# STM32H743 register map
File version: 2.4
CPU: CM7 r0p1, little endian, MPU, FPU, 4 interrupt priority bits
Registers are 32-bit, read-write, reset 0x0 unless marked. A register's access mark holds for its fields unless they carry their own. Offsets are from the block's base; [hi:lo] are bit positions; {n}, {i} and the like mark numbered series.

## LPUART1
Base 0x58000C00
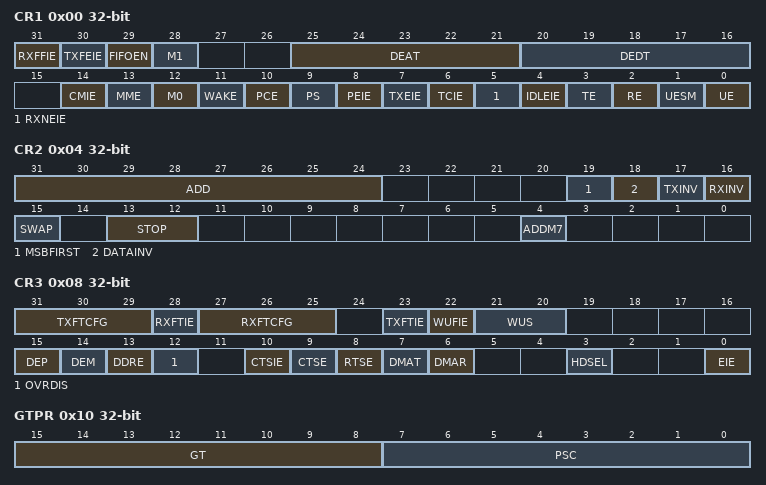
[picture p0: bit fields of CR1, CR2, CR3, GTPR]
0x00 CR1 — 控制寄存器 1
  [31] RXFFIE — 接收 FIFO 满中断使能
  [30] TXFEIE — 发送 FIFO 空中断使能
  [29] FIFOEN — FIFO 模式使能
  [28] M1 — 字长
  [25:21] DEAT — 驱动使能建立时间
  [20:16] DEDT — 驱动使能释放时间
  [14] CMIE — 字符匹配中断使能
  [13] MME — 静默模式使能
  [12] M0 — 字长
  [11] WAKE — 接收器唤醒方式
  [10] PCE — 校验控制使能
  [9] PS — 校验位选择
  [8] PEIE — 校验错误中断使能
  [7] TXEIE — 发送数据寄存器空中断使能
  [6] TCIE — 发送完成中断使能
  [5] RXNEIE — 接收数据寄存器非空中断使能
  [4] IDLEIE — 空闲线路中断使能
  [3] TE — 发送器使能
  [2] RE — 接收器使能
  [1] UESM — 停止模式下 USART 使能
  [0] UE — USART 使能
0x04 CR2 — 控制寄存器 2
  [31:24] ADD — USART 节点地址
  [19] MSBFIRST — 高位在前
  [18] DATAINV — 二进制数据取反
  [17] TXINV — TX 引脚有效电平取反
  [16] RXINV — RX 引脚有效电平取反
  [15] SWAP — TX/RX 引脚交换
  [13:12] STOP — 停止位
  [4] ADDM7 — 7 位地址检测 / 4 位地址检测
0x08 CR3 — 控制寄存器 3
  [31:29] TXFTCFG — 发送 FIFO 阈值配置
  [28] RXFTIE — 接收 FIFO 阈值中断使能
  [27:25] RXFTCFG — 接收 FIFO 阈值配置
  [23] TXFTIE — 发送 FIFO 阈值中断使能
  [22] WUFIE — 停止模式唤醒中断使能
  [21:20] WUS — 停止模式唤醒中断标志选择
  [15] DEP — 驱动使能极性选择
  [14] DEM — 驱动使能模式
  [13] DDRE — 接收错误时禁用 DMA
  [12] OVRDIS — 溢出禁用
  [10] CTSIE — CTS 中断使能
  [9] CTSE — CTS 使能
  [8] RTSE — RTS 使能
  [7] DMAT — DMA 发送使能
  [6] DMAR — DMA 接收使能
  [3] HDSEL — 半双工选择
  [0] EIE — 错误中断使能
0x0C BRR — 波特率寄存器
  [19:0] BRR — 波特率值
0x10 GTPR — 保护时间和预分频器寄存器
  [15:8] GT — 保护时间值
  [7:0] PSC — 预分频器值
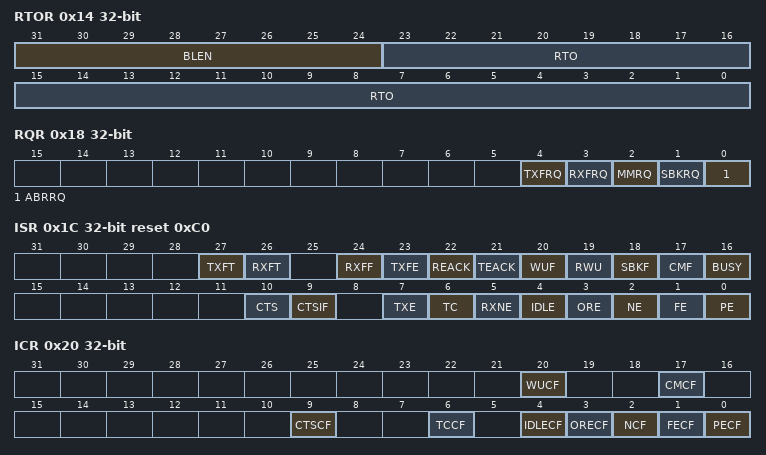
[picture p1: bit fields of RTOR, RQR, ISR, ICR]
0x14 RTOR — 接收超时寄存器
  [31:24] BLEN — 块长度
  [23:0] RTO — 接收超时值
0x18 RQR wo — 请求寄存器
  [4] TXFRQ — 发送数据刷新请求
  [3] RXFRQ — 接收数据刷新请求
  [2] MMRQ — 静默模式请求
  [1] SBKRQ — 发送间隔符请求
  [0] ABRRQ — 自动波特率请求
0x1C ISR ro reset 0xC0 — 中断和状态寄存器
  [27] TXFT — 发送 FIFO 阈值标志
  [26] RXFT — 接收 FIFO 阈值标志
  [24] RXFF — 接收 FIFO 满
  [23] TXFE — 发送 FIFO 空
  [22] REACK — 接收器使能确认
  [21] TEACK — 发送器使能确认
  [20] WUF — 停止模式唤醒标志
  [19] RWU — 接收器静默
  [18] SBKF — 间隔符标志
  [17] CMF — 字符匹配标志
  [16] BUSY — 忙标志
  [10] CTS — CTS 标志
  [9] CTSIF — CTS 中断标志
  [7] TXE — 发送数据寄存器空
  [6] TC — 发送完成
  [5] RXNE — 接收数据寄存器非空
  [4] IDLE — 空闲线路检测
  [3] ORE — 溢出错误
  [2] NE — 噪声错误
  [1] FE — 帧错误
  [0] PE — 校验错误
0x20 ICR wo — 中断标志清除寄存器
  [20] WUCF — 停止模式唤醒清除标志
  [17] CMCF — 字符匹配清除标志
  [9] CTSCF — CTS 清除标志
  [6] TCCF — 发送完成清除标志
  [4] IDLECF — 空闲线路检测清除标志
  [3] ORECF — 溢出错误清除标志
  [2] NCF — 噪声检测清除标志
  [1] FECF — 帧错误清除标志
  [0] PECF — 校验错误清除标志
0x24 RDR ro — 接收数据寄存器
  [8:0] RDR — 接收数据值
0x28 TDR — 发送数据寄存器
  [8:0] TDR — 发送数据值
0x2C PRESC — 预分频器寄存器
  [3:0] PRESCALER — 时钟预分频器

## SYSCFG — 系统配置控制器
Base 0x58000400
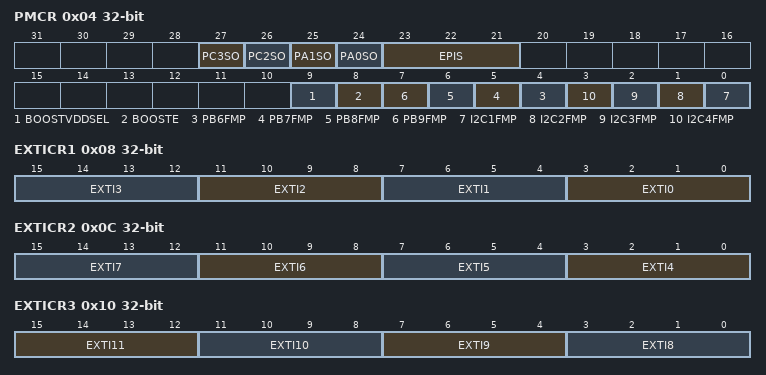
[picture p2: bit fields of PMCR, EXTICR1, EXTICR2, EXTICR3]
0x04 PMCR — 外设模式配置寄存器
  [27] PC3SO — PC3 开关断开
  [26] PC2SO — PC2 开关断开
  [25] PA1SO — PA1 开关断开
  [24] PA0SO — PA0 开关断开
  [23:21] EPIS — 以太网 PHY 接口选择
  [9] BOOSTVDDSEL — 模拟开关电源电压选择
  [8] BOOSTE — 升压器使能
  [n-2] PB{n}FMP (n=6..9) — PB{n} 快速模式+
  [n-1] I2C{n}FMP (n=1..4) — I2C{n} 快速模式+
0x08 EXTICR1 — 外部中断配置寄存器 1
  [4n+3:4n] EXTI{n} (n=0..3) — EXTIx 配置（x = 0 至 3）
0x0C EXTICR2 — 外部中断配置寄存器 2
  [4n-13:4n-16] EXTI{n} (n=4..7) — EXTIx 配置（x = 4 至 7）
0x10 EXTICR3 — 外部中断配置寄存器 3
  [15:12] EXTI11 — EXTIx 配置（x = 8 至 11）
  [11:8] EXTI10 — EXTI10 配置
  [7:4] EXTI9 — EXTIx 配置（x = 8 至 11）
  [3:0] EXTI8 — EXTIx 配置（x = 8 至 11）
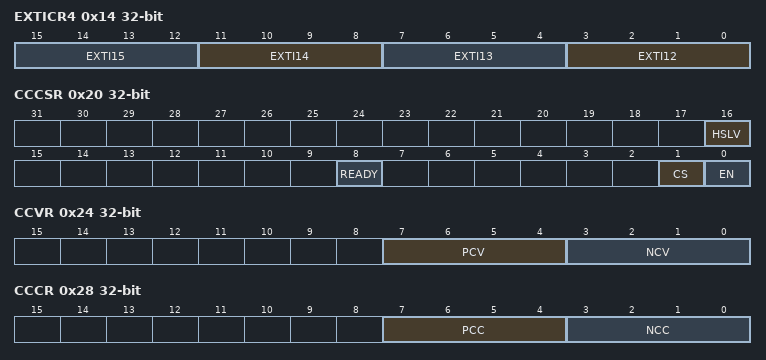
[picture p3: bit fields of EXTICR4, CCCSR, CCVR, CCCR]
0x14 EXTICR4 — 外部中断配置寄存器 4
  [4n-45:4n-48] EXTI{n} (n=12..15) — EXTIx 配置（x = 12 至 15）
0x20 CCCSR — 补偿单元控制/状态寄存器
  [16] HSLV — 低压高速模式
  [8] READY — 补偿单元就绪标志
  [1] CS — 代码选择
  [0] EN — 使能
0x24 CCVR ro — SYSCFG 补偿单元值寄存器
  [7:4] PCV — PMOS 补偿值
  [3:0] NCV — NMOS 补偿值
0x28 CCCR — SYSCFG 补偿单元代码寄存器
  [7:4] PCC — PMOS 补偿代码
  [3:0] NCC — NMOS 补偿代码
0x2C PWRCR — SYSCFG 电源控制寄存器
  [3:0] ODEN — 超速模式使能
0x124 PKGR ro — SYSCFG 封装寄存器
  [3:0] PKG — 封装类型
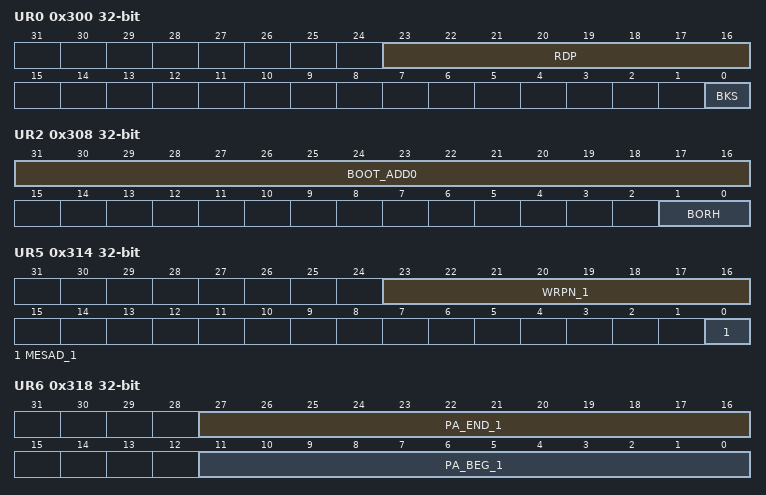
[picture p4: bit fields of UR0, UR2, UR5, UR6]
0x300 UR0 ro — SYSCFG 用户寄存器 0
  [23:16] RDP — 读出保护
  [0] BKS — 存储体交换
0x308 UR2 — SYSCFG 用户寄存器 2
  [31:16] BOOT_ADD0 — 启动地址 0
  [1:0] BORH — 欠压复位阈值等级
0x30C UR3 — SYSCFG 用户寄存器 3
  [31:16] BOOT_ADD1 — 启动地址 1
0x310 UR4 ro — SYSCFG 用户寄存器 4
  [16] MEPAD_1 — 存储体 1 禁用批量擦除保护区
0x314 UR5 ro — SYSCFG 用户寄存器 5
  [23:16] WRPN_1 — Flash 存储体 1 写保护
  [0] MESAD_1 — 存储体 1 禁用批量擦除安全区
0x318 UR6 ro — SYSCFG 用户寄存器 6
  [27:16] PA_END_1 — 存储体 1 保护区结束地址
  [11:0] PA_BEG_1 — 存储体 1 保护区起始地址
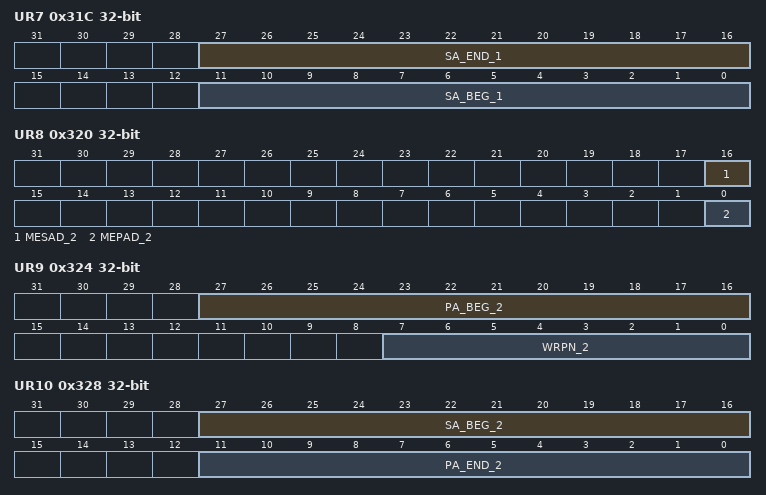
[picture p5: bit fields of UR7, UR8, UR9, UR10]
0x31C UR7 ro — SYSCFG 用户寄存器 7
  [27:16] SA_END_1 — 存储体 1 安全区结束地址
  [11:0] SA_BEG_1 — 存储体 1 安全区起始地址
0x320 UR8 ro — SYSCFG 用户寄存器 8
  [16] MESAD_2 — 存储体 2 禁用批量擦除安全区
  [0] MEPAD_2 — 存储体 2 禁用批量擦除保护区
0x324 UR9 ro — SYSCFG 用户寄存器 9
  [27:16] PA_BEG_2 — 存储体 2 保护区起始地址
  [7:0] WRPN_2 — Flash 存储体 2 写保护
0x328 UR10 ro — SYSCFG 用户寄存器 10
  [27:16] SA_BEG_2 — 存储体 2 安全区起始地址
  [11:0] PA_END_2 — 存储体 2 保护区结束地址
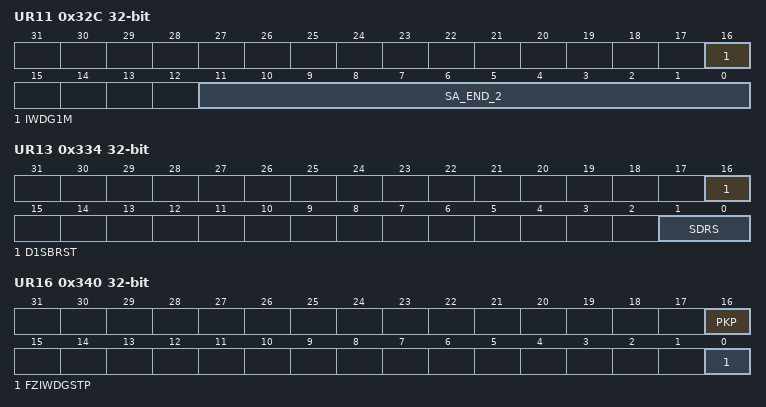
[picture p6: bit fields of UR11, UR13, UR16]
0x32C UR11 ro — SYSCFG 用户寄存器 11
  [16] IWDG1M — 独立看门狗 1 模式
  [11:0] SA_END_2 — 存储体 2 安全区结束地址
0x330 UR12 ro — SYSCFG 用户寄存器 12
  [16] SECURE — 安全模式
0x334 UR13 ro — SYSCFG 用户寄存器 13
  [16] D1SBRST — D1 待机复位
  [1:0] SDRS — 安全 DTCM RAM 大小
0x338 UR14 — SYSCFG 用户寄存器 14
  [0] D1STPRST — D1 停止复位
0x33C UR15 ro — SYSCFG 用户寄存器 15
  [16] FZIWDGSTB — 待机模式下冻结独立看门狗
0x340 UR16 ro — SYSCFG 用户寄存器 16
  [16] PKP — 私钥已编程
  [0] FZIWDGSTP — 停止模式下冻结独立看门狗
0x344 UR17 ro — SYSCFG 用户寄存器 17
  [0] IO_HSLV — I/O 高速/低压
